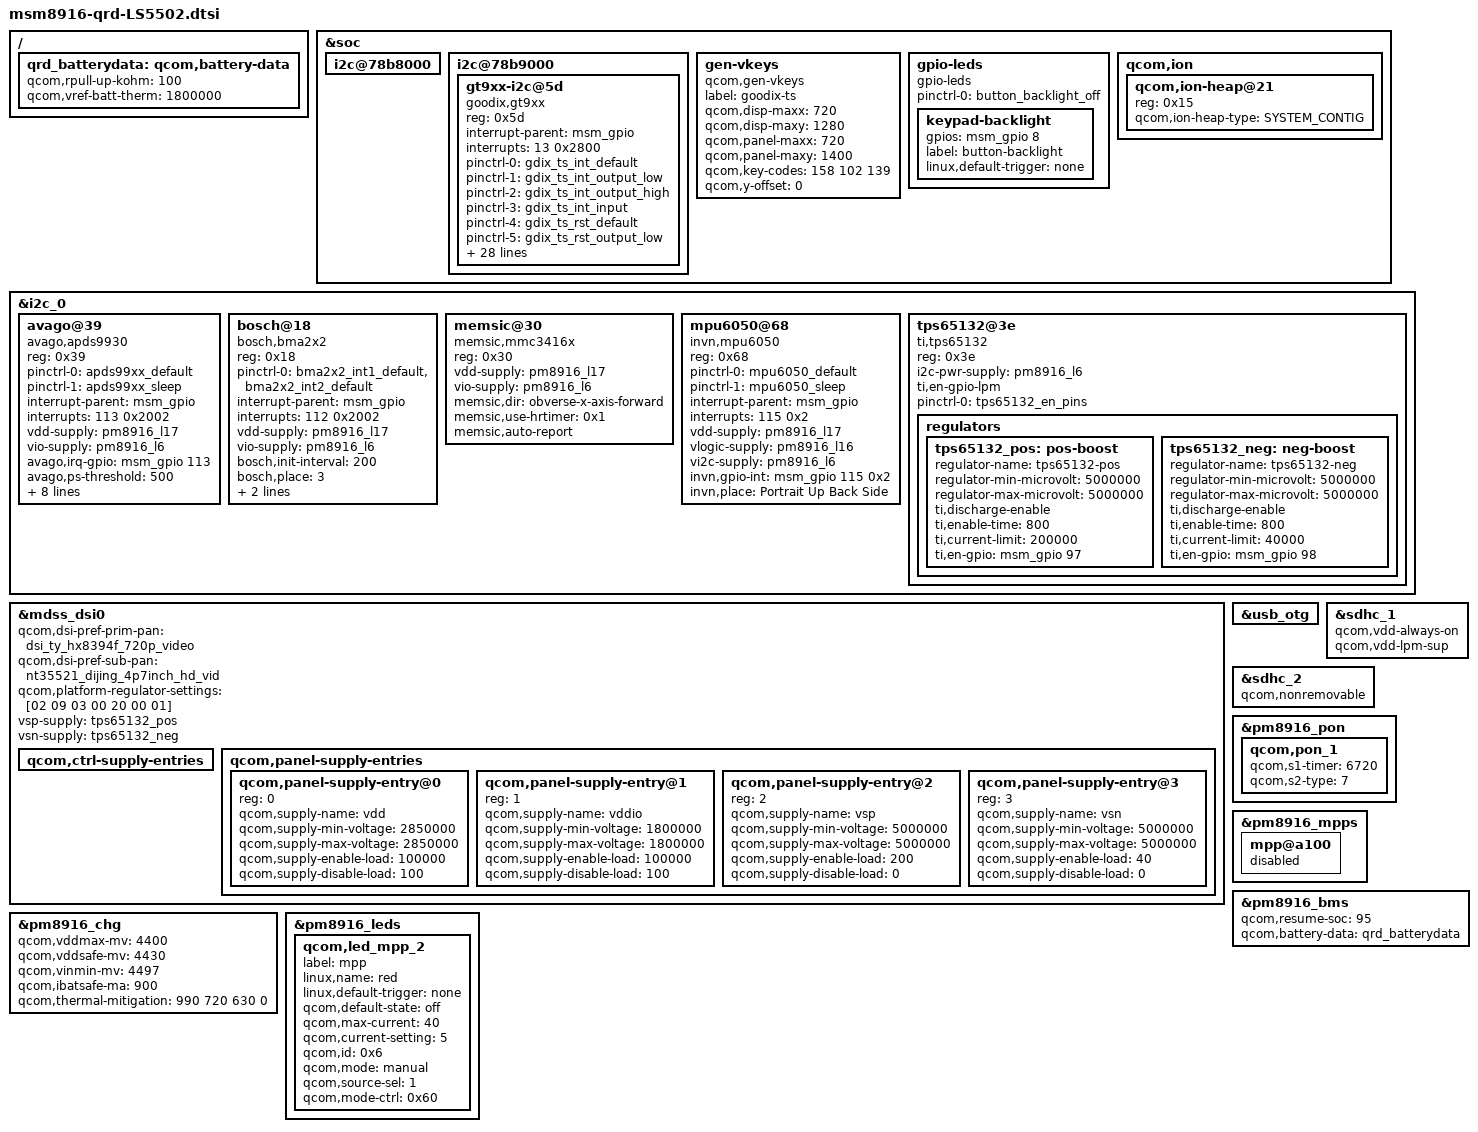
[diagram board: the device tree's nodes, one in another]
/* Copyright (c) 2020, The Linux Foundation. All rights reserved.
*  Copyright (c) 2020, the_shahnawaz_sheikh (sheikhshahnawaz41299).
*
* This program is free software; you can redistribute it and/or modify
* it under the terms of the GNU General Public License version 2 and
* only version 2 as published by the Free Software Foundation.
*
* This program is distributed in the hope that it will be useful,
* but WITHOUT ANY WARRANTY; without even the implied warranty of
* MERCHANTABILITY or FITNESS FOR A PARTICULAR PURPOSE.  See the
* GNU General Public License for more details.
*/

#include "dsi-panel-ty-hx8394f-720p-video.dtsi"
#include "dsi-panel-ty-ili9881c-720p-video.dtsi"
#include "dsi_panel_dijing_nt35521h_hsd4p7_hd_video.dtsi"
#include "msm8916-camera-sensor-qrd-skui.dtsi"
#include "msm8916-pinctrl-lyf.dtsi"

&soc {
    
	i2c@78b8000 {
	
	  /delete-node/ smb1360-chg-fg@14;
	
	};
	

	i2c@78b9000 { /* BLSP1 QUP5 */
	     
		/delete-node/ focaltech@38;
		
		/*focaltech@38 {
			compatible = "focaltech,5x06";
			reg = <0x38>;
			interrupt-parent = <&msm_gpio>;
			interrupts = <13 0x2002>;
			vdd-supply = <&pm8916_l17>;
			vcc_i2c-supply = <&pm8916_l6>;
			pinctrl-names = "pmx_ts_active","pmx_ts_suspend","pmx_ts_release";
			pinctrl-0 = <&ts_int_active &ts_reset_active>;
			pinctrl-1 = <&ts_int_suspend &ts_reset_suspend>;
			pinctrl-2 = <&ts_release>;
			focaltech,name = "ft5336";
			focaltech,family-id = <0x14>;
			focaltech,reset-gpio = <&msm_gpio 12 0x0>;
			focaltech,irq-gpio = <&msm_gpio 13 0x2002>;
			focaltech,display-coords = <0 0 720 1280>;
			focaltech,panel-coords = <0 0 720 1424>;
			focaltech,button-map= <139 102 158>;
			focaltech,no-force-update;
			focaltech,i2c-pull-up;
			focaltech,group-id = <1>;
			focaltech,hard-reset-delay-ms = <20>;
			focaltech,soft-reset-delay-ms = <200>;
			focaltech,num-max-touches = <5>;
			focaltech,fw-delay-aa-ms = <30>;
			focaltech,fw-delay-55-ms = <30>;
			focaltech,fw-upgrade-id1 = <0x79>;
			focaltech,fw-upgrade-id2 = <0x11>;
			focaltech,fw-delay-readid-ms = <10>;
			focaltech,fw-delay-era-flsh-ms = <2000>;
			focaltech,fw-auto-cal;
			focaltech,ignore-id-check;
		};*/

		gt9xx-i2c@5d {
			compatible = "goodix,gt9xx";
			reg = <0x5d>;
			interrupt-parent = <&msm_gpio>;
			interrupts = <13 0x2800>;
			pinctrl-names = "gdix_ts_int_default",
				"gdix_ts_int_output_low",
				"gdix_ts_int_output_high",
				"gdix_ts_int_input",
				"gdix_ts_rst_default",
				"gdix_ts_rst_output_low",
				"gdix_ts_rst_output_high",
				"gdix_ts_rst_input";
			pinctrl-0 = <&gdix_ts_int_default>;
			pinctrl-1 = <&gdix_ts_int_output_low>;
			pinctrl-2 = <&gdix_ts_int_output_high>;
			pinctrl-3 = <&gdix_ts_int_input>;
			pinctrl-4 = <&gdix_ts_rst_default>;
			pinctrl-5 = <&gdix_ts_rst_output_low>;
			pinctrl-6 = <&gdix_ts_rst_output_high>;
			pinctrl-7 = <&gdix_ts_rst_input>;
			reset-gpios = <&msm_gpio 12 0x00>;
			irq-gpios = <&msm_gpio 13 0x2800>;
			irq-flags = <1>;
			vdd_ana-supply = <&pm8916_l16>;
			vcc_i2c-supply = <&pm8916_l6>;
			touchscreen-max-id = <5>;
			touchscreen-size-x = <720>;
			touchscreen-size-y = <1280>;
			touchscreen-max-w = <512>;
			touchscreen-max-p = <512>;
			touchscreen-key-map = <158>, <102>, <139>; /*KEY_BACK=158，KEY_HOMEPAGE=102, KEY_MENU=139*/
			goodix,slide-wakeup = <0>;
			goodix,type-a-report = <0>;
			goodix,driver-send-cfg = <1>;
			goodix,resume-in-workqueue = <0>;
			goodix,int-sync = <1>;
			goodix,swap-x2y = <0>;
			goodix,esd-protect = <1>;
			goodix,auto-update = <0>;
			goodix,auto-update-cfg = <0>;
			goodix,power-off-sleep = <1>;
			goodix,pen-suppress-finger = <0>;
			goodix,cfg-data0 = [41 d0 02 00 05 05 35 01 01 0f 28 05 50 32 03 05 00 00 00 00 00 00 00 17 19 1f 14 8c 2e 0e 44 42 d4 07 00 00 00 5b 02 11 00 00 00 00 00 00 00 08 0a 00 00 32 64 94 c5 02 07 00 00 04 94 35 00 86 3d 00 7b 46 00 71 51 00 69 5d 00 69 18 40 60 00 f0 4a 3a ff ff 27 00 00 00 00 00 00 00 00 00 00 00 00 00 00 00 00 00 00 00 00 00 00 00 00 00 00 02 04 06 08 0a 0c 0e 10 12 14 16 18 1a 1c 00 00 00 00 00 00 00 00 00 00 00 00 00 00 00 00 00 02 04 06 08 0a 0c 0f 10 12 13 14 16 18 1c 1d 1e 1f 20 21 22 24 26 28 29 2a 00 00 00 00 00 00 00 00 00 00 00 00 00 00 00 00 2f 01];
			goodix,cfg-data2 = [41 d0 02 00 05 05 35 01 01 08 28 05 50 32 03 05 00 00 00 00 00 00 00 17 19 1e 14 8c 2c 0d 44 42 d4 07 00 00 01 42 02 11 00 00 00 00 00 00 00 08 0a 00 00 32 64 94 c5 02 07 00 00 04 96 35 00 87 3d 00 7a 46 00 6f 51 00 67 5d 00 67 18 38 58 00 f0 4a 3a ff ff 27 00 00 00 00 00 00 00 00 00 00 00 00 00 00 00 00 00 00 00 00 00 00 00 00 00 00 02 04 06 08 0a 0c 0e 10 12 14 16 18 1a ff 00 00 00 00 00 00 00 00 00 00 00 00 00 00 00 00 16 18 1c 1d 1e 1f 20 21 22 24 26 28 14 13 12 10 0f 0c 0a 08 06 04 02 00 ff ff 00 00 00 00 00 00 00 00 00 00 00 00 00 00 00 00 d8 01];
		};
	};
	
	gen-vkeys {
		compatible = "qcom,gen-vkeys";
		label = "goodix-ts";
		qcom,disp-maxx = <720>;
		qcom,disp-maxy = <1280>;
		qcom,panel-maxx = <720>;
		qcom,panel-maxy = <1400>;
		qcom,key-codes = <158 102 139>;
		qcom,y-offset = <0>;
	};
	
	gpio-leds {
		compatible = "gpio-leds";
		status = "okay";
		pinctrl-names = "default";
		pinctrl-0 = <&button_backlight_off>;

		keypad-backlight {
			gpios = <&msm_gpio 8 0>;
			label = "button-backlight";
			linux,default-trigger = "none";
		};
	};
	
	qcom,ion {
	   
	   qcom,ion-heap@21 {
				reg = <0x15>;
				qcom,ion-heap-type = "SYSTEM_CONTIG";
			};
	};

	
};

&i2c_0 { /* BLSP1 QUP2 */
	avago@39 { /* Ambient light and proximity sensor */
		compatible = "avago,apds9930";
		reg = <0x39>;
		pinctrl-names = "default","sleep";
		pinctrl-0 = <&apds99xx_default>;
		pinctrl-1 = <&apds99xx_sleep>;
		interrupt-parent = <&msm_gpio>;
		interrupts = <113 0x2002>;
		vdd-supply = <&pm8916_l17>;
		vio-supply = <&pm8916_l6>;
		avago,irq-gpio = <&msm_gpio 113 0x2002>;
		avago,ps-threshold = <500>;
		avago,ps-hysteresis-threshold = <400>;
		avago,ps-pulse = <30>;
		avago,ps-pgain = <0>;
		avago,als-B = <186>;
		avago,als-C = <75>;
		avago,als-D = <129>;
		avago,ga-value = <768>;
		avago,default-cal;
		status = "ok";
	};

	bosch@18 { /* Accelerometer sensor */
		compatible = "bosch,bma2x2";
		reg = <0x18>;
		pinctrl-names = "default";
		pinctrl-0 = <&bma2x2_int1_default &bma2x2_int2_default>;
		interrupt-parent = <&msm_gpio>;
		interrupts = <112 0x2002>;
		vdd-supply = <&pm8916_l17>;
		vio-supply = <&pm8916_l6>;
		bosch,init-interval = <200>;
		bosch,place = <3>;
		bosch,gpio-int1 = <&msm_gpio 112 0x2002>;
		bosch,gpio-int2 = <&msm_gpio 114 0x2002>;
		status = "ok";
	};

	memsic@30 { /* Magnetic field sensor */
		compatible = "memsic,mmc3416x";
		reg = <0x30>;
		vdd-supply = <&pm8916_l17>;
		vio-supply = <&pm8916_l6>;
		memsic,dir = "obverse-x-axis-forward";
		memsic,use-hrtimer = <0x1>;
		memsic,auto-report;
		status = "ok";
	};

	mpu6050@68 {
		compatible = "invn,mpu6050";
		reg = <0x68>;
		pinctrl-names = "mpu_default","mpu_sleep";
		pinctrl-0 = <&mpu6050_default>;
		pinctrl-1 = <&mpu6050_sleep>;
		interrupt-parent = <&msm_gpio>;
		interrupts = <115 0x2>;
		vdd-supply = <&pm8916_l17>;
		vlogic-supply = <&pm8916_l16>;
		vi2c-supply = <&pm8916_l6>;
		invn,gpio-int = <&msm_gpio 115 0x2>;
		invn,place = "Portrait Up Back Side";
		status = "ok";
	};
	
	tps65132@3e {
				compatible = "ti,tps65132";
				reg = <0x3e>;
				i2c-pwr-supply = <&pm8916_l6>;
				ti,en-gpio-lpm;
				pinctrl-names = "default";
				pinctrl-0 = <&tps65132_en_pins>;
				status = "ok";

				regulators {

					tps65132_pos:pos-boost {
						regulator-name = "tps65132-pos";
						regulator-min-microvolt = <5000000>;
						regulator-max-microvolt = <5000000>;
						ti,discharge-enable;
						ti,enable-time = <800>;
						ti,current-limit = <200000>;
						ti,en-gpio = <&msm_gpio 97 0>;
					};

					tps65132_neg: neg-boost {
						regulator-name = "tps65132-neg";
						regulator-min-microvolt = <5000000>;
						regulator-max-microvolt = <5000000>;
						ti,discharge-enable;
						ti,enable-time = <800>;
						ti,current-limit = <40000>;
						ti,en-gpio = <&msm_gpio 98 0>;
					};
				};
			};
};


&mdss_dsi0 {
	qcom,dsi-pref-prim-pan = <&dsi_ty_hx8394f_720p_video>;
	
	qcom,dsi-pref-sub-pan = <&nt35521_dijing_4p7inch_hd_vid>;
	
	qcom,platform-regulator-settings = [02 09 03 00 20 00 01];
	
	vsp-supply = <&tps65132_pos>;
	vsn-supply = <&tps65132_neg>;

	qcom,ctrl-supply-entries {
		
	};

	qcom,panel-supply-entries {
			#address-cells = <1>;
			#size-cells = <0>;

			qcom,panel-supply-entry@0 {
				reg = <0>;
				qcom,supply-name = "vdd";
				qcom,supply-min-voltage = <2850000>;
				qcom,supply-max-voltage = <2850000>;
				qcom,supply-enable-load = <100000>;
				qcom,supply-disable-load = <100>;
			};
                 

			qcom,panel-supply-entry@1 {
				reg = <1>;
				qcom,supply-name = "vddio";
				qcom,supply-min-voltage = <1800000>;
				qcom,supply-max-voltage = <1800000>;
				qcom,supply-enable-load = <100000>;
				qcom,supply-disable-load = <100>;
			};
			
			qcom,panel-supply-entry@2 {
					reg = <2>;
					qcom,supply-name = "vsp";
					qcom,supply-min-voltage = <5000000>;
					qcom,supply-max-voltage = <5000000>;
					qcom,supply-enable-load = <200>;
					qcom,supply-disable-load = <0>;
				};

				qcom,panel-supply-entry@3 {
					reg = <3>;
					qcom,supply-name = "vsn";
					qcom,supply-min-voltage = <5000000>;
					qcom,supply-max-voltage = <5000000>;
					qcom,supply-enable-load = <40>;
					qcom,supply-disable-load = <0>;
				};
			
		};

};

/ {
	qrd_batterydata: qcom,battery-data {
	   qcom,rpull-up-kohm = <100>;
		qcom,vref-batt-therm = <1800000>;
		
		#include "batterydata-qrd-ty-4v4-2920mah.dtsi"
		#include "batterydata-qrd-ty-atl-4v4-2920mah.dtsi"
		
	};
};

&usb_otg {
    /delete-property/ qcom,usbid-gpio;
	/delete-property/	pinctrl-names;
	/delete-property/	pinctrl-0;
	/delete-property/	vbus_otg-supply;
};

&sdhc_1 {
  qcom,vdd-always-on;
			qcom,vdd-lpm-sup;
};

&sdhc_2 {
  qcom,nonremovable;
};

&pm8916_pon {
  qcom,pon_1 {
		qcom,s1-timer = <6720>;
		qcom,s2-type = <7>;
	};
};

&pm8916_mpps {
   
        mpp@a100 {
			status = "disabled";
		};
};
   
   

&pm8916_chg {
  
  qcom,vddmax-mv = <4400>;
  qcom,vddsafe-mv = <4430>;
  qcom,vinmin-mv = <4497>;
  qcom,ibatsafe-ma = <900>;
  qcom,thermal-mitigation = <990 720 630 0>;
  status = "ok";
  /delete-property/ qcom,use-external-charger;
};

&pm8916_bms {
	status = "ok";
	/delete-property/ qcom,disable-bms;
	qcom,resume-soc = <95>;
	qcom,battery-data = <&qrd_batterydata>;
};

&pm8916_leds {
	status = "okay";
	
	qcom,led_mpp_2 {
						label = "mpp";
						linux,name = "red";
						linux,default-trigger = "none";
						qcom,default-state = "off";
						qcom,max-current = <40>;
						qcom,current-setting = <5>;
						qcom,id = <0x6>;
						qcom,mode = "manual";
						qcom,source-sel = <1>;
						qcom,mode-ctrl = <0x60>;
					};
};


